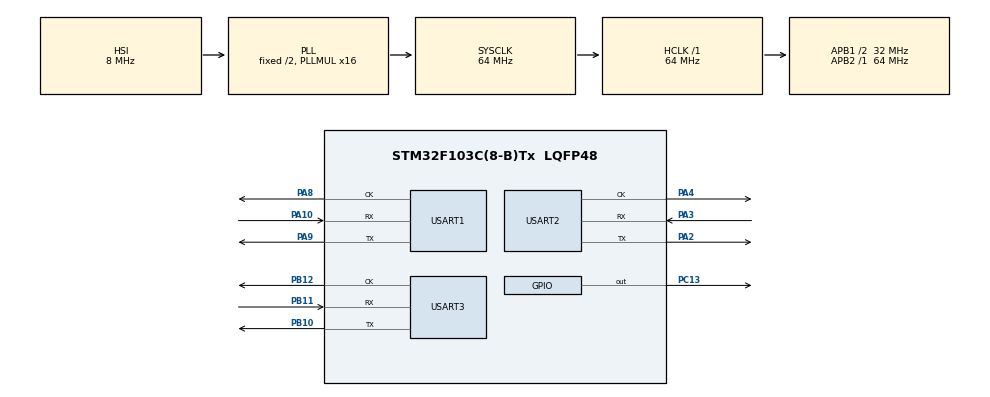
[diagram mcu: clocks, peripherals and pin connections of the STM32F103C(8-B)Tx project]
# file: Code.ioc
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Mcu.Family=STM32F1
Mcu.Name=STM32F103C(8-B)Tx
Mcu.Package=LQFP48
NVIC.PriorityGroup=NVIC_PRIORITYGROUP_4
PA10.Mode=Synchronous
PA10.Signal=USART1_RX
PA2.Mode=Synchronous
PA2.Signal=USART2_TX
PA3.Mode=Synchronous
PA3.Signal=USART2_RX
PA4.Mode=Synchronous
PA4.Signal=USART2_CK
PA8.Mode=Synchronous
PA8.Signal=USART1_CK
PA9.Mode=Synchronous
PA9.Signal=USART1_TX
PB10.Mode=Synchronous
PB10.Signal=USART3_TX
PB11.Mode=Synchronous
PB11.Signal=USART3_RX
PB12.Mode=Synchronous
PB12.Signal=USART3_CK
PC13-TAMPER-RTC.Signal=GPIO_Output
ProjectManager.HeapSize=0x200
ProjectManager.StackSize=0x400
ProjectManager.TargetToolchain=MDK-ARM V5.32
RCC.AHBFreq_Value=64000000
RCC.APB1CLKDivider=RCC_HCLK_DIV2
RCC.APB1Freq_Value=32000000
RCC.APB1TimFreq_Value=64000000
RCC.APB2Freq_Value=64000000
RCC.APB2TimFreq_Value=64000000
RCC.HCLKFreq_Value=64000000
RCC.PLLMUL=RCC_PLL_MUL16
RCC.SYSCLKFreq_VALUE=64000000
RCC.SYSCLKSource=RCC_SYSCLKSOURCE_PLLCLK
RCC.USBFreq_Value=64000000
USART1.VirtualMode=VM_SYNC
USART2.VirtualMode=VM_SYNC
USART3.VirtualMode=VM_SYNC
VP_SYS_VS_ND.Mode=No_Debug
board=custom

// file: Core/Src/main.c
/* USER CODE BEGIN Header */
/**
  ******************************************************************************
  * @file           : main.c
  * @brief          : Main program body
  ******************************************************************************
  * @attention
  *
  * Copyright (c) 2024 STMicroelectronics.
  * All rights reserved.
  *
  * This software is licensed under terms that can be found in the LICENSE file
  * in the root directory of this software component.
  * If no LICENSE file comes with this software, it is provided AS-IS.
  *
  ******************************************************************************
  */
/* USER CODE END Header */
#include "main.h"
#include "usart.h"
#include "gpio.h"

void SystemClock_Config(void);

int main(void)
{

  /* MCU Configuration--------------------------------------------------------*/

  /* Reset of all peripherals, Initializes the Flash interface and the Systick. */
  HAL_Init();

  /* Configure the system clock */
  SystemClock_Config();

  /* Initialize all configured peripherals */
  MX_GPIO_Init();
  MX_USART1_Init();
  MX_USART2_Init();
  MX_USART3_Init();

  /* Infinite loop */
  while (1)
  {

    /* USER CODE BEGIN 3 */
      HAL_USART_Transmit(&husart1, "Hello World!\r\n", sizeof("Hello World!\r\n"), 100);
      HAL_USART_Transmit(&husart2, "Hello World!\r\n", sizeof("Hello World!\r\n"), 100);
      HAL_USART_Transmit(&husart3, "Hello World!\r\n", sizeof("Hello World!\r\n"), 100);
      HAL_Delay(100);

  }

  /* USER CODE END 3 */
}

void SystemClock_Config(void)
{
  RCC_OscInitTypeDef RCC_OscInitStruct = {0};
  RCC_ClkInitTypeDef RCC_ClkInitStruct = {0};

  /** Initializes the RCC Oscillators according to the specified parameters
  * in the RCC_OscInitTypeDef structure.
  */
  RCC_OscInitStruct.OscillatorType = RCC_OSCILLATORTYPE_HSI;
  RCC_OscInitStruct.HSIState = RCC_HSI_ON;
  RCC_OscInitStruct.HSICalibrationValue = RCC_HSICALIBRATION_DEFAULT;
  RCC_OscInitStruct.PLL.PLLState = RCC_PLL_ON;
  RCC_OscInitStruct.PLL.PLLSource = RCC_PLLSOURCE_HSI_DIV2;
  RCC_OscInitStruct.PLL.PLLMUL = RCC_PLL_MUL16;
  if (HAL_RCC_OscConfig(&RCC_OscInitStruct) != HAL_OK)
  {
    Error_Handler();
  }

  /** Initializes the CPU, AHB and APB buses clocks
  */
  RCC_ClkInitStruct.ClockType = RCC_CLOCKTYPE_HCLK|RCC_CLOCKTYPE_SYSCLK
                              |RCC_CLOCKTYPE_PCLK1|RCC_CLOCKTYPE_PCLK2;
  RCC_ClkInitStruct.SYSCLKSource = RCC_SYSCLKSOURCE_PLLCLK;
  RCC_ClkInitStruct.AHBCLKDivider = RCC_SYSCLK_DIV1;
  RCC_ClkInitStruct.APB1CLKDivider = RCC_HCLK_DIV2;
  RCC_ClkInitStruct.APB2CLKDivider = RCC_HCLK_DIV1;

  if (HAL_RCC_ClockConfig(&RCC_ClkInitStruct, FLASH_LATENCY_2) != HAL_OK)
  {
    Error_Handler();
  }
}

/* USER CODE BEGIN 4 */
 /*****************  发送字符串 **********************/

/* USER CODE END 4 */

void Error_Handler(void)
{
  __disable_irq();
  while (1)
  {
  }
}
